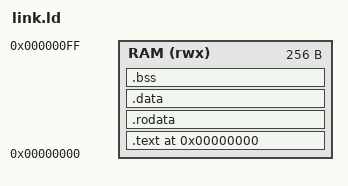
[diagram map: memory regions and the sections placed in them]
ENTRY(_start)

MEMORY {
    RAM (rwx) : ORIGIN = 0x00000000, LENGTH = 256
}

SECTIONS {
    .text 0x00000000 : {
        *(.text.start)   /* startup code goes first */
        *(.text*)
    } > RAM

    .rodata : {
        *(.rodata*)
    } > RAM

    .data : {
        *(.data*)
    } > RAM

    .bss : {
        __bss_start = .;
        *(.bss*)
        *(COMMON)
        __bss_end = .;
    } > RAM

    _stack_top = ORIGIN(RAM) + LENGTH(RAM);
}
